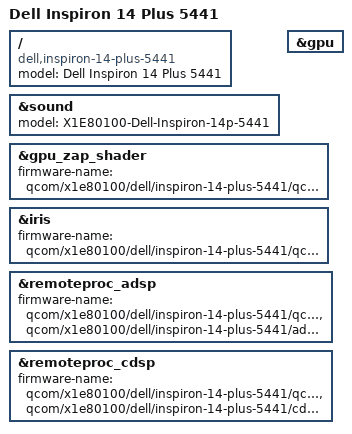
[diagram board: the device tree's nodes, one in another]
// SPDX-License-Identifier: BSD-3-Clause
/*
 * Copyright (c) 2026 Adam Szyma <adamszyma@wp.pl>
 */
/dts-v1/;
#include "hamoa.dtsi"
#include "x1-dell-thena.dtsi"

/ {
	model = "Dell Inspiron 14 Plus 5441";
	compatible = "dell,inspiron-14-plus-5441",
		     "qcom,x1p64100", "qcom,x1e80100";
};

&sound {
	model = "X1E80100-Dell-Inspiron-14p-5441";
};

&gpu {
	status = "okay";
};

&gpu_zap_shader {
	firmware-name = "qcom/x1e80100/dell/inspiron-14-plus-5441/qcdxkmsuc8380.mbn";
};

&iris {
	firmware-name = "qcom/x1e80100/dell/inspiron-14-plus-5441/qcvss8380.mbn";
	status = "okay";
};

&remoteproc_adsp {
	firmware-name = "qcom/x1e80100/dell/inspiron-14-plus-5441/qcadsp8380.mbn",
			"qcom/x1e80100/dell/inspiron-14-plus-5441/adsp_dtbs.elf";
	status = "okay";
};

&remoteproc_cdsp {
	firmware-name = "qcom/x1e80100/dell/inspiron-14-plus-5441/qccdsp8380.mbn",
			"qcom/x1e80100/dell/inspiron-14-plus-5441/cdsp_dtbs.elf";
	status = "okay";
};
